# CY8C5468AXI_LP106 register map
File version: 0.1
Registers are 8-bit, read-write, no defined reset value unless marked. A register's access mark holds for its fields unless they carry their own. Offsets are from the block's base; [hi:lo] are bit positions; 'fields as' and 'values as' point back to an identical list.

## SPIS
Base 0x00000000
0x40006404 SPIS_RX_DATA
0x40006404 SPIS_TX_DATA
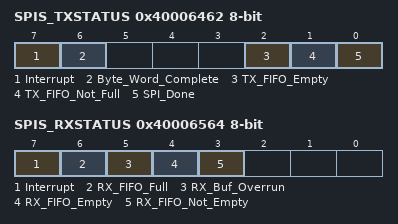
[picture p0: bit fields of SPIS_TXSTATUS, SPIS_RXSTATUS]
0x40006462 SPIS_TXSTATUS
  [7] Interrupt ro — Set when interrupt occurs
  [6] Byte_Word_Complete ro — Set when a byte/word transmit has completed
  [2] TX_FIFO_Empty ro — Set when the TX Data FIFO is empty
  [1] TX_FIFO_Not_Full ro — Set when the TX Data FIFO is not full
  [0] SPI_Done ro — Set when all of the data in the transmit FIFO has been sent. Set when Byte/Word Complete has been set and TX Data FIFO is empty
0x40006564 SPIS_RXSTATUS
  [7] Interrupt ro — Set when interrupt occurs
  [6] RX_FIFO_Full ro — Set when the RX Data FIFO is full
  [5] RX_Buf_Overrun ro — Set when RX Data has overrun the 4 byte/word FIFO without being moved to the RX buffer cmemory array (if one exists)
  [4] RX_FIFO_Empty ro — Set when the RX Data FIFO is empty
  [3] RX_FIFO_Not_Empty ro — Set when the RX Data FIFO is not empty. That is, at least one byte/word is in the RX FIFO

## QuadDec_2
Base 0x00000000
0x4000640C QuadDec_2_Cnt16_COUNTER 16-bit — Counter value
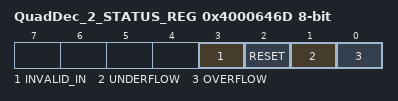
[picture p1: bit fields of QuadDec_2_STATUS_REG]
0x4000646D QuadDec_2_STATUS_REG — Quadrature Decoder Status Register
  [3] INVALID_IN ro — Invalid state transition on the A and B inputs
  [2] RESET ro — Counter Reset due index
  [1] UNDERFLOW ro — Counter underflow
  [0] OVERFLOW ro — Counter overflow

## QuadDec_2_Cnt16
Base 0x00000000
0x4000640C QuadDec_2_Cnt16_COUNTER 16-bit — UDB.A0 - Current Counter Value
0x4000642C QuadDec_2_Cnt16_PERIOD 16-bit — UDB.D0 - Assigned Period
0x4000643C QuadDec_2_Cnt16_COMPARE 16-bit — UDB.D1 - Assigned Compare Value
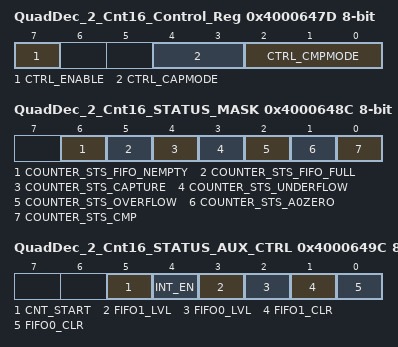
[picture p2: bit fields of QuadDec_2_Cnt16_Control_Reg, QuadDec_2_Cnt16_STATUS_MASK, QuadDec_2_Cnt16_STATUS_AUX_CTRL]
0x4000647D QuadDec_2_Cnt16_Control_Reg — UDB Control Register - Assigned Control Register Value
  [7] CTRL_ENABLE — Enable Counter
  [4:3] CTRL_CAPMODE — Capture mode
  [2:0] CTRL_CMPMODE — Compare mode
0x4000648C QuadDec_2_Cnt16_STATUS_MASK — UDB Status bits Interrupt Mask Enable Register
  [6] COUNTER_STS_FIFO_NEMPTY — FIFO Not Empty Status
  [5] COUNTER_STS_FIFO_FULL — FIFO Full Status
  [4] COUNTER_STS_CAPTURE — Capture Status
  [3] COUNTER_STS_UNDERFLOW — Underflow status
  [2] COUNTER_STS_OVERFLOW — Overflow status
  [1] COUNTER_STS_A0ZERO — A0 Zero ouput status
  [0] COUNTER_STS_CMP — Compare output status
0x4000649C QuadDec_2_Cnt16_STATUS_AUX_CTRL — UDB Auxilliary Control Register
  [5] CNT_START — FIFO0 clear
    0=E_CNT_START0 (Disable counter); 1=E_CNT_START1 (Enable counter)
  [4] INT_EN
    0=E_INT_EN0 (Interrupt disabled); 1=E_INT_EN1 (Interrupt enabled)
  [3] FIFO1_LVL — FIFO level
    0=E_FIFO_LVL_0 (FIFO LVL: input mode: FIFO not full; output mode: FIFO not empty); 1=E_FIFO_LVL_1 (FIFO LVL: input mode: FIFO at least 1/2 empty; output mode: FIFO at least 1/2 full)
  [2] FIFO0_LVL — FIFO level
    values as FIFO1_LVL
  [1] FIFO1_CLR — FIFO1 clear
    0=E_FIFO_CLR_0 (Normal FIFO operation); 1=E_FIFO_CLR_1 (Clear FIFO state)
  [0] FIFO0_CLR — FIFO0 clear
    values as FIFO1_CLR

## MIS_Stat
Base 0x40006464
0x00 MIS_Stat_STATUS_REG
0x20 MIS_Stat_MASK_REG
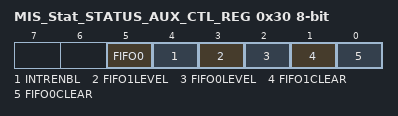
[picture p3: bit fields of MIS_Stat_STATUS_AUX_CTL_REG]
0x30 MIS_Stat_STATUS_AUX_CTL_REG
  [5] FIFO0 — FIFO0 clear
    1=ENABLED (Enable counter); 0=DISABLED (Disable counter)
  [4] INTRENBL — Enables or disables the Interrupt
    1=ENABLED (Interrupt enabled); 0=DISABLED (Interrupt disabled)
  [3] FIFO1LEVEL — FIFO level
    1=ENABLED (FIFO LVL: input mode: FIFO at least 1/2 empty; output mode: FIFO at least 1/2 full); 0=DISABLED (FIFO LVL: input mode: FIFO not full; output mode: FIFO not empty)
  [2] FIFO0LEVEL — FIFO level
    values as FIFO1LEVEL
  [1] FIFO1CLEAR — FIFO clear
    1=ENABLED (Clear FIFO state); 0=DISABLED (Normal FIFO operation)
  [0] FIFO0CLEAR — FIFO clear
    values as FIFO1CLEAR

## MIS_Reg
Base 0x40006576
0x00 MIS_Reg_CONTROL_REG
